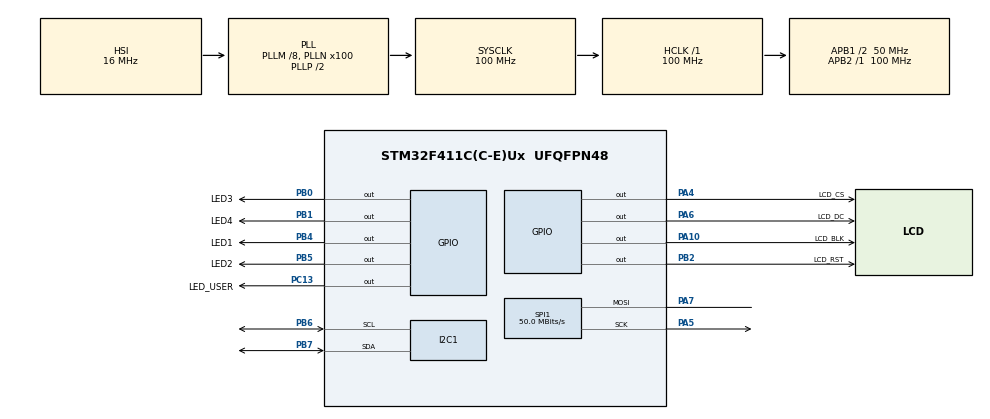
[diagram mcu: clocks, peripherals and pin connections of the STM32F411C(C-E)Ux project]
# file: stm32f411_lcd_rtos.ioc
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FREERTOS.Tasks01=defaultTask,0,128,StartDefaultTask,Default,NULL,Dynamic,NULL,NULL
Mcu.Family=STM32F4
Mcu.Name=STM32F411C(C-E)Ux
Mcu.Package=UFQFPN48
NVIC.PriorityGroup=NVIC_PRIORITYGROUP_4
PA10.GPIO_Label=LCD_BLK
PA10.Signal=GPIO_Output
PA13.Mode=Serial_Wire
PA13.Signal=SYS_JTMS-SWDIO
PA14.Mode=Serial_Wire
PA14.Signal=SYS_JTCK-SWCLK
PA4.GPIO_Label=LCD_CS
PA4.Signal=GPIO_Output
PA5.Mode=Simplex_Bidirectional_Master
PA5.Signal=SPI1_SCK
PA6.GPIO_Label=LCD_DC
PA6.Signal=GPIO_Output
PA7.Mode=Simplex_Bidirectional_Master
PA7.Signal=SPI1_MOSI
PB0.GPIO_Label=LED3
PB0.Signal=GPIO_Output
PB1.GPIO_Label=LED4
PB1.Signal=GPIO_Output
PB2.GPIO_Label=LCD_RST
PB2.Signal=GPIO_Output
PB4.GPIO_Label=LED1
PB4.Signal=GPIO_Output
PB5.GPIO_Label=LED2
PB5.Signal=GPIO_Output
PB6.Mode=I2C
PB6.Signal=I2C1_SCL
PB7.Mode=I2C
PB7.Signal=I2C1_SDA
PC13-ANTI_TAMP.GPIO_Label=LED_USER
PC13-ANTI_TAMP.Signal=GPIO_Output
PH0\ -\ OSC_IN.Mode=HSE-External-Clock-Source
PH0\ -\ OSC_IN.Signal=RCC_OSC_IN
PH1\ -\ OSC_OUT.Mode=HSE-External-Clock-Source
PH1\ -\ OSC_OUT.Signal=RCC_OSC_OUT
ProjectManager.HeapSize=0x2000
ProjectManager.StackSize=0x2000
ProjectManager.TargetToolchain=SW4STM32
RCC.48MHZClocksFreq_Value=50000000
RCC.AHBFreq_Value=100000000
RCC.APB1CLKDivider=RCC_HCLK_DIV2
RCC.APB1Freq_Value=50000000
RCC.APB1TimFreq_Value=100000000
RCC.APB2Freq_Value=100000000
RCC.APB2TimFreq_Value=100000000
RCC.CortexFreq_Value=100000000
RCC.HCLKFreq_Value=100000000
RCC.HSE_VALUE=25000000
RCC.HSI_VALUE=16000000
RCC.LSE_VALUE=32768
RCC.PLLM=8
RCC.PLLN=100
RCC.SYSCLKFreq_VALUE=100000000
RCC.SYSCLKSource=RCC_SYSCLKSOURCE_PLLCLK
RCC.VCOOutputFreq_Value=200000000
SPI1.CalculateBaudRate=50.0 MBits/s
SPI1.Direction=SPI_DIRECTION_1LINE
SPI1.Mode=SPI_MODE_MASTER
SPI1.VirtualType=VM_MASTER
VP_FREERTOS_VS_CMSIS_V1.Mode=CMSIS_V1
board=custom

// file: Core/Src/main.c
/* USER CODE BEGIN Header */
/**
  ******************************************************************************
  * @file           : main.c
  * @brief          : Main program body
  ******************************************************************************
  * @attention
  *
  * Copyright (c) 2022 STMicroelectronics.
  * All rights reserved.
  *
  * This software is licensed under terms that can be found in the LICENSE file
  * in the root directory of this software component.
  * If no LICENSE file comes with this software, it is provided AS-IS.
  *
  ******************************************************************************
  */
/* USER CODE END Header */
#include "main.h"
#include "cmsis_os.h"
#include "i2c.h"
#include "spi.h"
#include "gpio.h"

/* USER CODE BEGIN Includes */
#include "lvgl.h"
#include "lv_conf.h"
#include "lv_port_disp.h"
#include "lv_demos.h"
/* USER CODE END Includes */

void SystemClock_Config(void);
void MX_FREERTOS_Init(void);

int main(void)
{

  /* MCU Configuration--------------------------------------------------------*/

  /* Reset of all peripherals, Initializes the Flash interface and the Systick. */
  HAL_Init();

  /* Configure the system clock */
  SystemClock_Config();

  /* Initialize all configured peripherals */
  MX_GPIO_Init();
  MX_I2C1_Init();
  MX_SPI1_Init();
  /* USER CODE BEGIN 2 */
//  lv_init();
//  lv_port_disp_init();

//  lv_demo_music();
//lv_demo_widgets();
  /* USER CODE END 2 */

  /* Call init function for freertos objects (in freertos.c) */
//  MX_FREERTOS_Init();
//  /* Start scheduler */
//  osKernelStart();

  /* We should never get here as control is now taken by the scheduler */
  /* Infinite loop */
  while (1)
  {

    /* USER CODE BEGIN 3 */
      HAL_GPIO_TogglePin(LED1_GPIO_Port, LED1_Pin);
      HAL_GPIO_TogglePin(LED2_GPIO_Port, LED2_Pin);
      HAL_GPIO_TogglePin(LED3_GPIO_Port, LED3_Pin);
      HAL_GPIO_TogglePin(LED4_GPIO_Port, LED4_Pin);
      HAL_Delay(500);
//    lv_timer_handler();
//      HAL_Delay(5);
  }
  /* USER CODE END 3 */
}

void SystemClock_Config(void)
{
  RCC_OscInitTypeDef RCC_OscInitStruct = {0};
  RCC_ClkInitTypeDef RCC_ClkInitStruct = {0};

  /** Configure the main internal regulator output voltage
  */
  __HAL_RCC_PWR_CLK_ENABLE();
  __HAL_PWR_VOLTAGESCALING_CONFIG(PWR_REGULATOR_VOLTAGE_SCALE1);
  /** Initializes the RCC Oscillators according to the specified parameters
  * in the RCC_OscInitTypeDef structure.
  */
  RCC_OscInitStruct.OscillatorType = RCC_OSCILLATORTYPE_HSI;
  RCC_OscInitStruct.HSIState = RCC_HSI_ON;
  RCC_OscInitStruct.HSICalibrationValue = RCC_HSICALIBRATION_DEFAULT;
  RCC_OscInitStruct.PLL.PLLState = RCC_PLL_ON;
  RCC_OscInitStruct.PLL.PLLSource = RCC_PLLSOURCE_HSI;
  RCC_OscInitStruct.PLL.PLLM = 8;
  RCC_OscInitStruct.PLL.PLLN = 100;
  RCC_OscInitStruct.PLL.PLLP = RCC_PLLP_DIV2;
  RCC_OscInitStruct.PLL.PLLQ = 4;
  if (HAL_RCC_OscConfig(&RCC_OscInitStruct) != HAL_OK)
  {
    Error_Handler();
  }
  /** Initializes the CPU, AHB and APB buses clocks
  */
  RCC_ClkInitStruct.ClockType = RCC_CLOCKTYPE_HCLK|RCC_CLOCKTYPE_SYSCLK
                              |RCC_CLOCKTYPE_PCLK1|RCC_CLOCKTYPE_PCLK2;
  RCC_ClkInitStruct.SYSCLKSource = RCC_SYSCLKSOURCE_PLLCLK;
  RCC_ClkInitStruct.AHBCLKDivider = RCC_SYSCLK_DIV1;
  RCC_ClkInitStruct.APB1CLKDivider = RCC_HCLK_DIV2;
  RCC_ClkInitStruct.APB2CLKDivider = RCC_HCLK_DIV1;

  if (HAL_RCC_ClockConfig(&RCC_ClkInitStruct, FLASH_LATENCY_3) != HAL_OK)
  {
    Error_Handler();
  }
}

void Error_Handler(void)
{
  __disable_irq();
  while (1)
  {
  }
}
